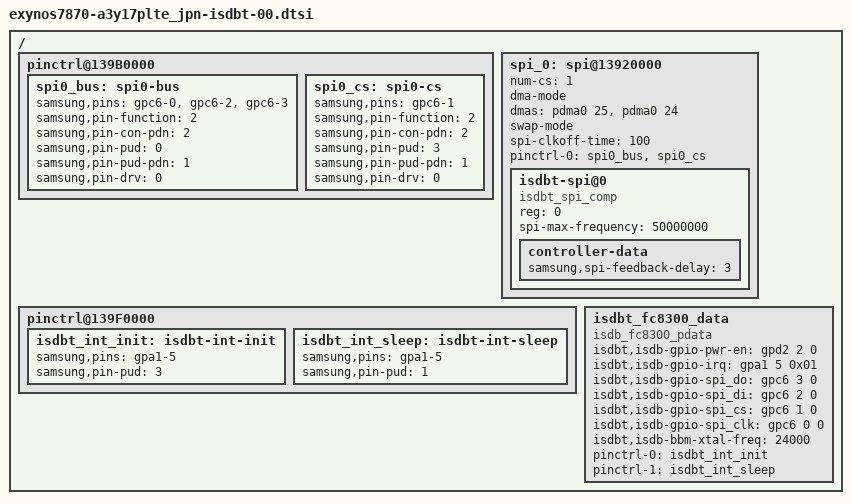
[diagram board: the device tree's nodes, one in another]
 /* Copyright (c) 2012-2014, The Linux Foundation. All rights reserved.
 *
 * This program is free software; you can redistribute it and/or modify
 * it under the terms of the GNU General Public License version 2 and
 * only version 2 as published by the Free Software Foundation.
 *
 * This program is distributed in the hope that it will be useful,
 * but WITHOUT ANY WARRANTY; without even the implied warranty of
 * MERCHANTABILITY or FITNESS FOR A PARTICULAR PURPOSE.  See the
 * GNU General Public License for more details.
 */

/{
	pinctrl@139B0000 {
		spi0_bus: spi0-bus {
			samsung,pins = "gpc6-0", "gpc6-2", "gpc6-3";
			samsung,pin-function = <2>;
			samsung,pin-con-pdn = <2>; /* IN */
			samsung,pin-pud = <0>;
			samsung,pin-pud-pdn = <1>; /* PD */
			samsung,pin-drv = <0>;
		};
		
		spi0_cs: spi0-cs {
			samsung,pins = "gpc6-1";
			samsung,pin-function = <2>;
			samsung,pin-con-pdn = <2>; /* IN */
			samsung,pin-pud = <3>;
			samsung,pin-pud-pdn = <1>; /* PD */
			samsung,pin-drv = <0>;
		};
	};

	spi_0: spi@13920000 {
		#address-cells = <1>;
		#size-cells = <0>;
		num-cs = <1>;

		dma-mode;
		dmas = <&pdma0 25
			&pdma0 24>;
		dma-names = "tx", "rx";

		swap-mode;
		status = "ok";
		spi-clkoff-time = <100>;
		
		pinctrl-names = "default";
		pinctrl-0 = <&spi0_bus &spi0_cs>;

		isdbt-spi@0 {
			compatible = "isdbt_spi_comp";
			reg = <0>;
			spi-max-frequency = <50000000>;
			controller-data {
				samsung,spi-feedback-delay = <3>;
			};
		};
	};

	pinctrl@139F0000 {
		isdbt_int_init: isdbt-int-init {
			samsung,pins = "gpa1-5";
			samsung,pin-pud = <3>;
		};
		isdbt_int_sleep: isdbt-int-sleep {
			samsung,pins = "gpa1-5";
			samsung,pin-pud = <1>;
		};
	};

	isdbt_fc8300_data {
		compatible = "isdb_fc8300_pdata";
		isdbt,isdb-gpio-pwr-en = <&gpd2 2 0>;
		isdbt,isdb-gpio-irq = <&gpa1 5 0x01>;
		isdbt,isdb-gpio-spi_do = <&gpc6 3 0>;
		isdbt,isdb-gpio-spi_di = <&gpc6 2 0>;
		isdbt,isdb-gpio-spi_cs = <&gpc6 1 0>;
		isdbt,isdb-gpio-spi_clk = <&gpc6 0 0>;
		isdbt,isdb-bbm-xtal-freq = <24000>;
		/* isdbt,ldo_vdd_1p8 = "VDD_1.8V_ESE"; */
		/* clocks = <&clock 1>; */
		/* clock-names = "isdbt_clkout";*/
		
		pinctrl-names = "isdbt_on", "isdbt_off";
		pinctrl-0 = <&isdbt_int_init>;
		pinctrl-1 = <&isdbt_int_sleep>;
	};

};
